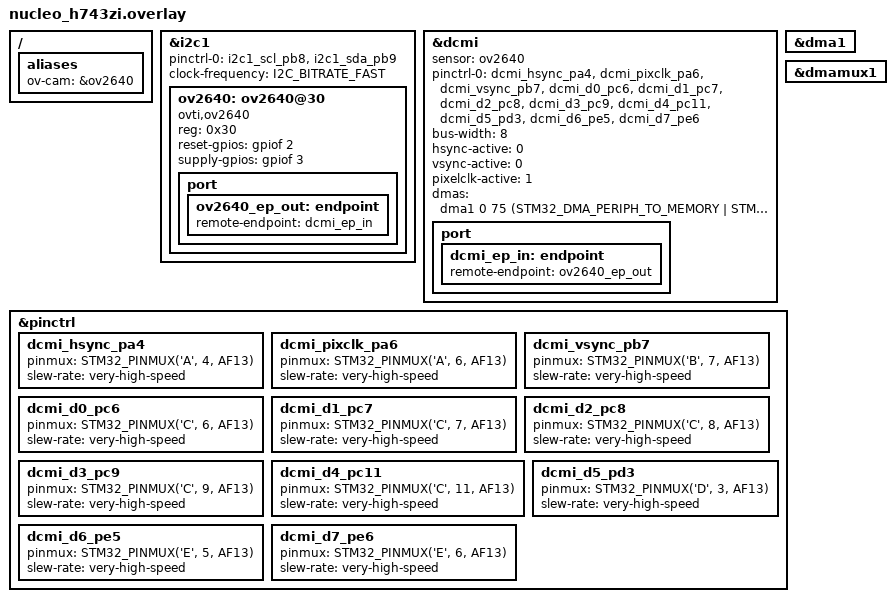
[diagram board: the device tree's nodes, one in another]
/*
 * Copyright (c) 2024 Charles Dias <charlesdias.cd@outlook.com>
 *
 * SPDX-License-Identifier: Apache-2.0
 *
 */

/ {
	aliases {
		ov-cam = &ov2640;
	};
};


&i2c1 {
	pinctrl-0 = <&i2c1_scl_pb8 &i2c1_sda_pb9>;
	pinctrl-names = "default";
	status = "okay";
	clock-frequency = <I2C_BITRATE_FAST>;

	ov2640: ov2640@30 {
		compatible = "ovti,ov2640";
		reg = <0x30>;
		status = "okay";
		reset-gpios = <&gpiof 2 GPIO_ACTIVE_HIGH>;
		supply-gpios = <&gpiof 3 GPIO_ACTIVE_HIGH>;

		port {
			ov2640_ep_out: endpoint {
				remote-endpoint = <&dcmi_ep_in>;
			};
		};
	};
};

&dcmi {
	status = "okay";
	sensor = <&ov2640>;
	pinctrl-0 = <&dcmi_hsync_pa4 &dcmi_pixclk_pa6 &dcmi_vsync_pb7
		&dcmi_d0_pc6 &dcmi_d1_pc7 &dcmi_d2_pc8 &dcmi_d3_pc9
		&dcmi_d4_pc11 &dcmi_d5_pd3 &dcmi_d6_pe5 &dcmi_d7_pe6>;
	pinctrl-names = "default";
	bus-width = <8>;
	hsync-active = <0>;
	vsync-active = <0>;
	pixelclk-active = <1>;
	dmas = <&dma1 0 75 (STM32_DMA_PERIPH_TO_MEMORY | STM32_DMA_PERIPH_NO_INC |
		STM32_DMA_MEM_INC | STM32_DMA_PERIPH_8BITS | STM32_DMA_MEM_32BITS |
		STM32_DMA_PRIORITY_HIGH) STM32_DMA_FIFO_1_4>;

	port {
		dcmi_ep_in: endpoint {
			remote-endpoint = <&ov2640_ep_out>;
		};
	};
};

&dma1 {
	status = "okay";
};

&dmamux1 {
	status = "okay";
};

// FIXME: move to pinctrl dtsi files
&pinctrl{

	/* DCMI_HSYNC */

	/omit-if-no-ref/ dcmi_hsync_pa4: dcmi_hsync_pa4 {
		pinmux = <STM32_PINMUX('A', 4, AF13)>;
		slew-rate = "very-high-speed";
	};

	/* DCMI_PIXCLK */

	/omit-if-no-ref/ dcmi_pixclk_pa6: dcmi_pixclk_pa6 {
		pinmux = <STM32_PINMUX('A', 6, AF13)>;
		slew-rate = "very-high-speed";
	};

	/* DCMI_VSYNC */

	/omit-if-no-ref/ dcmi_vsync_pb7: dcmi_vsync_pb7 {
		pinmux = <STM32_PINMUX('B', 7, AF13)>;
		slew-rate = "very-high-speed";
	};

	/* DCMI_D0 */

	/omit-if-no-ref/ dcmi_d0_pc6: dcmi_d0_pc6 {
		pinmux = <STM32_PINMUX('C', 6, AF13)>;
		slew-rate = "very-high-speed";
	};

	/* DCMI_D1 */

	/omit-if-no-ref/ dcmi_d1_pc7: dcmi_d1_pc7 {
		pinmux = <STM32_PINMUX('C', 7, AF13)>;
		slew-rate = "very-high-speed";
	};

	/* DCMI_D2 */

	/omit-if-no-ref/ dcmi_d2_pc8: dcmi_d2_pc8 {
		pinmux = <STM32_PINMUX('C', 8, AF13)>;
		slew-rate = "very-high-speed";
	};

	/* DCMI_D3 */

	/omit-if-no-ref/ dcmi_d3_pc9: dcmi_d3_pc9 {
		pinmux = <STM32_PINMUX('C', 9, AF13)>;
		slew-rate = "very-high-speed";
	};

	/* DCMI_D4 */

	/omit-if-no-ref/ dcmi_d4_pc11: dcmi_d4_pc11 {
		pinmux = <STM32_PINMUX('C', 11, AF13)>;
		slew-rate = "very-high-speed";
	};

	/* DCMI_D5 */

	/omit-if-no-ref/ dcmi_d5_pd3: dcmi_d5_pd3 {
		pinmux = <STM32_PINMUX('D', 3, AF13)>;
		slew-rate = "very-high-speed";
	};

	/* DCMI_D6 */

	/omit-if-no-ref/ dcmi_d6_pe5: dcmi_d6_pe5 {
		pinmux = <STM32_PINMUX('E', 5, AF13)>;
		slew-rate = "very-high-speed";
	};

	/* DCMI_D7 */

	/omit-if-no-ref/ dcmi_d7_pe6: dcmi_d7_pe6 {
		pinmux = <STM32_PINMUX('E', 6, AF13)>;
		slew-rate = "very-high-speed";
	};
};
